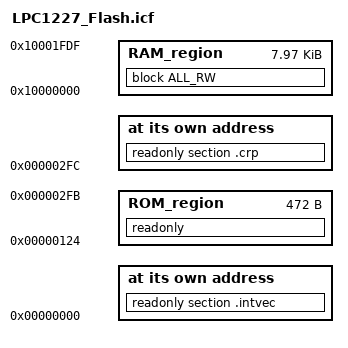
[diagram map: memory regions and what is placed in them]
define symbol intvec_start = 0x00000000;
define memory mem with size = 4G;
initialize by copy { readwrite };
do not initialize  { section .noinit };

/***********************************************/
/* FLASH (ROM) memory */
/***********************************************/
define symbol ROM_start  = 0x00000124;
define symbol ROM_end  = 0x00002000;
define symbol CRP_LOCATION = 0x2FC;


/* define the user part of the rom */
define region ROM_region = mem:[from ROM_start  to CRP_LOCATION - 1] | 
		               [from CRP_LOCATION + 4 to ROM_end ] ;

/* rom placements */
place at address mem:intvec_start { readonly section .intvec };
place at address mem:CRP_LOCATION { readonly section .crp };
place in ROM_region { readonly };

/***********************************************/
/* RAM memory */
/***********************************************/
define symbol LPC_1227_RAM_start   = 0x10000000;
define symbol LPC_1227_RAM_end     = 0x10001FFF;

define symbol IAP_RESERVED = 0x20; /* top 32 bytes reserved for IAP commands */

define symbol USER_RAM_START = LPC_1227_RAM_start;
/* this is defined to make sure last 2K ram is left for BIST */
define symbol USER_RAM_END = LPC_1227_RAM_end - IAP_RESERVED; 

/***********************************************/
/* Sizes of stack, heap, ClassB reserved RAM memory */
/***********************************************/
define symbol size_cstack = 0x800;      /* 2K of stack */
/*define symbol size_heap = 0x200;      no heap at the moment */  
define symbol size_ClassB_Data = 0x10;  /* 4 32-bit words */

keep { object IEC60335_B_UserData.o };
keep { object LPC1227_TargetConfig.o };

define block CSTACK with alignment = 8, size = size_cstack { };
/* define block HEAP with alignment = 8, size = size_heap { }; */
define block CLASSB_DATA with alignment = 8, size = size_ClassB_Data { object IEC60335_B_UserData.o };
define block ALL_RW with fixed order { block CLASSB_DATA, readwrite, block CSTACK };


/* define the user part of the ram */
/* modified to take care of IAP requirements */
define region RAM_region = mem:[from USER_RAM_START to USER_RAM_END];

/* ram placements */
/* to ensure specific order is preserved */
place in RAM_region   { block ALL_RW };

/* IEC60335 related, used to determine memory layout  */
define exported symbol IEC60335_TOP_RAM_POST = LPC_1227_RAM_end+1;
define exported symbol IEC60335_BOTTOM_RAM_POST = LPC_1227_RAM_start;

define exported symbol IEC60335_TOP_RAM_BIST = LPC_1227_RAM_end+1;
